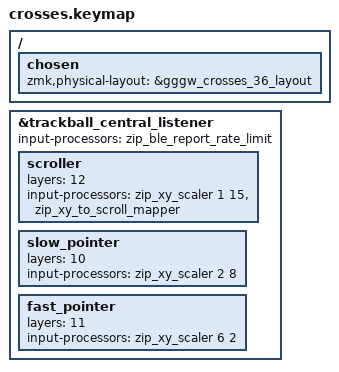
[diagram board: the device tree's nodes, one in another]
#include <behaviors.dtsi>
#define CONFIG_WIRELESS
#define CONFIG_TRACKBALL
#define ZMK_BASE_LAYER(name, LT, RT, LM, RM, LB, RB, LH, RH)  \
    ZMK_LAYER(                                                                 \
        name,                                                                  \
                 LT RT                                                         \
                 LM RM                                                         \
                 LB RB                                                         \
       SMART_NUM LH RH SMART_SHIFT                                             \
    )

#include "zmk-helpers/key-labels/36.h"

#define KEYS_L LT0 LT1 LT2 LT3 LT4 LM0 LM1 LM2 LM3 LM4 LB0 LB1 LB2 LB3 LB4 // Left-hand keys.
#define KEYS_R RT0 RT1 RT2 RT3 RT4 RM0 RM1 RM2 RM3 RM4 RB0 RB1 RB2 RB3 RB4 // Right-hand keys.
#define PM_KEY &soft_off

/ {
    chosen {
        zmk,physical-layout = &gggw_crosses_36_layout;
    };
};

&trackball_central_listener {
	input-processors = <&zip_ble_report_rate_limit>;
    scroller: scroller {
			layers           = <12>;
			input-processors = <
			   &zip_xy_scaler 1 15             // Scales the scroll speed
			   &zip_xy_to_scroll_mapper        // Converts XY movement to scroll events
							   >;
		};
    slow_pointer: slow_pointer {
        layers           = <10>;
        input-processors = <&zip_xy_scaler 2 8>;
    };
    fast_pointer: fast_pointer {
        layers           = <11>;
        input-processors = <&zip_xy_scaler 6 2>;
    };
};

#include "base.keymap"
